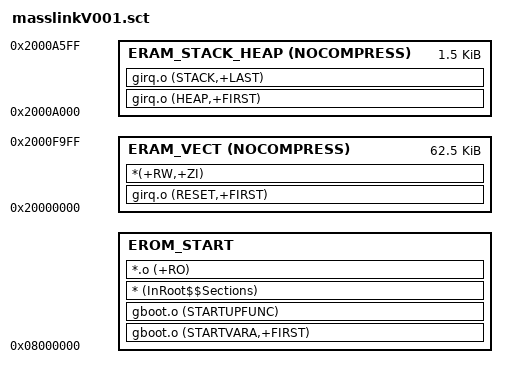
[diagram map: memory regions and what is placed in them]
LROM_BOOT 0x08000000 (0x20000)
{
	EROM_START +0
	{
		gboot.o (STARTVARA,+FIRST)
		gboot.o (STARTUPFUNC)
		* (InRoot$$Sections)
		*.o (+RO)
	}
	ERAM_VECT 0x20000000 NOCOMPRESS (0x10000 - 0x600)
	{
		girq.o (RESET,+FIRST)
		*(+RW,+ZI)
	}
	ERAM_STACK_HEAP 0x2000A000 NOCOMPRESS (0x600)
	{
		girq.o (HEAP,+FIRST)
		girq.o (STACK,+LAST)
	}
}

